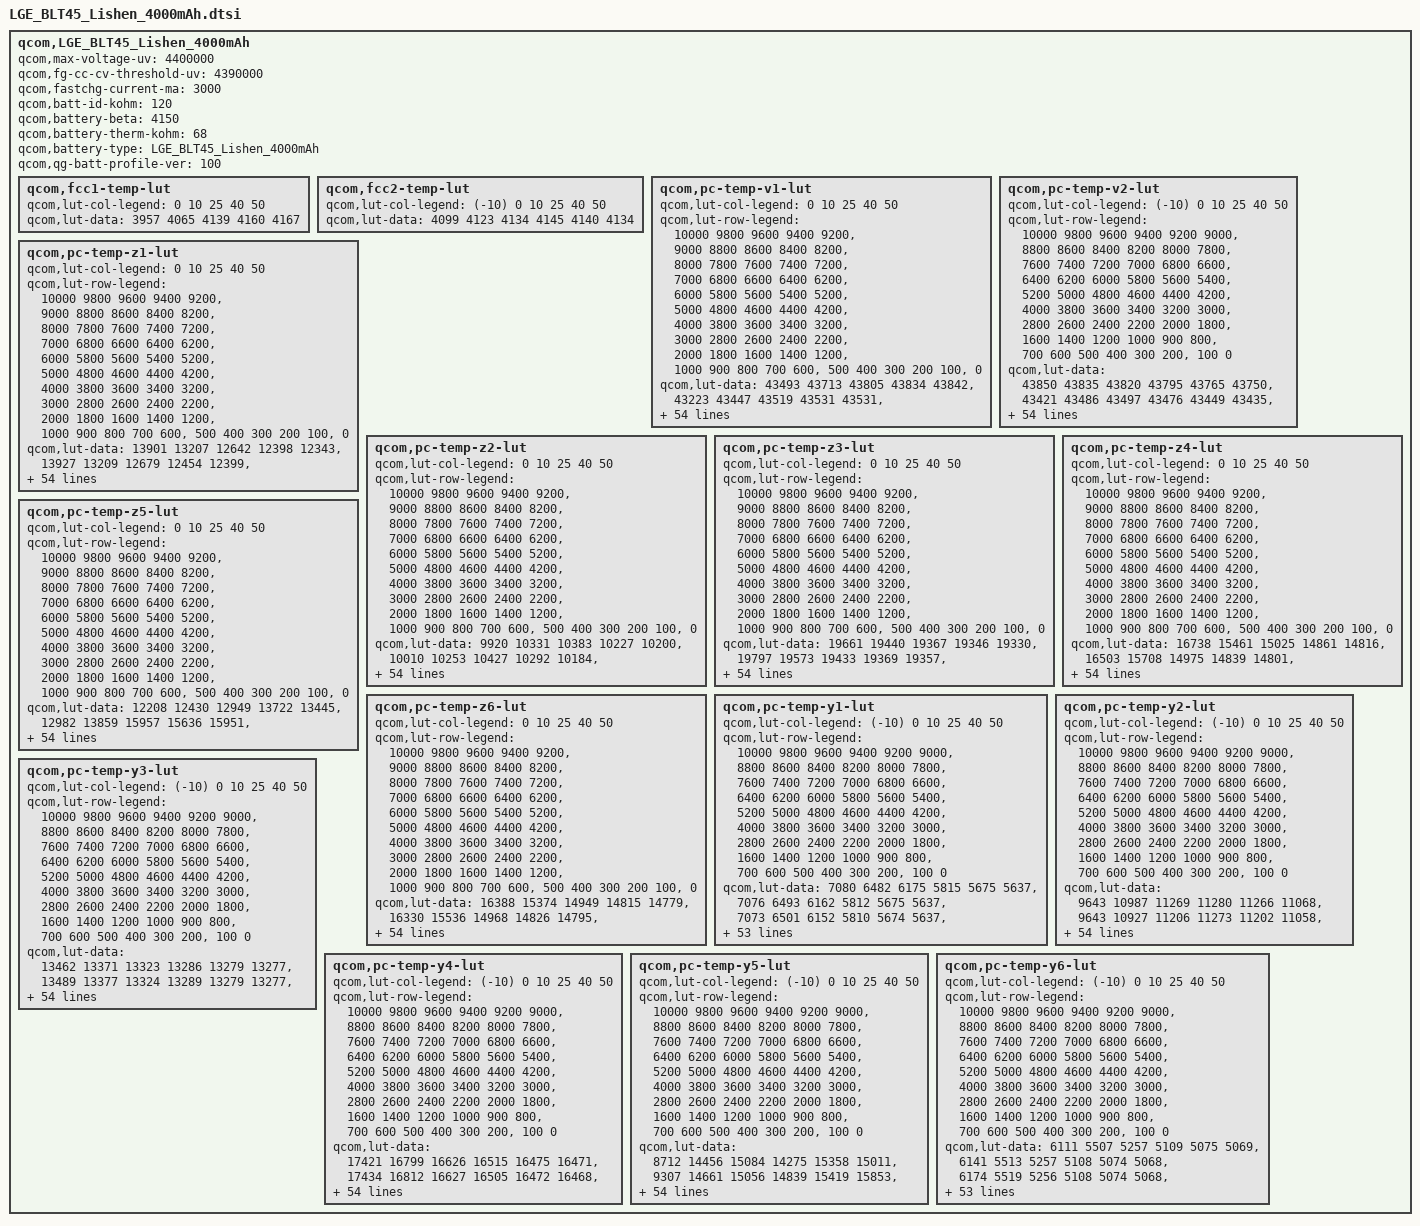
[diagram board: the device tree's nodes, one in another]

qcom,LGE_BLT45_Lishen_4000mAh {
    /* 3833608_LGE_BLT45_4000mAh_averaged_MasterSlave_Feb14th2019 */
    qcom,max-voltage-uv = <4400000>;
    qcom,fg-cc-cv-threshold-uv = <4390000>;
    qcom,fastchg-current-ma = <3000>;
    qcom,batt-id-kohm = <120>;
    qcom,battery-beta = <4150>;
    qcom,battery-therm-kohm = <68>;
    qcom,battery-type = "LGE_BLT45_Lishen_4000mAh";
    qcom,qg-batt-profile-ver = <100>;

	qcom,fcc1-temp-lut {
		qcom,lut-col-legend = <0 10 25 40 50>;
		qcom,lut-data = <3957 4065 4139 4160 4167>;
	};

	qcom,fcc2-temp-lut {
		qcom,lut-col-legend = <(-10) 0 10 25 40 50>;
		qcom,lut-data = <4099 4123 4134 4145 4140 4134>;
	};

	qcom,pc-temp-v1-lut {
		qcom,lut-col-legend = <0 10 25 40 50>;
		qcom,lut-row-legend = <10000 9800 9600 9400 9200>,
			<9000 8800 8600 8400 8200>,
			<8000 7800 7600 7400 7200>,
			<7000 6800 6600 6400 6200>,
			<6000 5800 5600 5400 5200>,
			<5000 4800 4600 4400 4200>,
			<4000 3800 3600 3400 3200>,
			<3000 2800 2600 2400 2200>,
			<2000 1800 1600 1400 1200>,
			<1000 900 800 700 600>,
			<500 400 300 200 100>,
			<0>;
		qcom,lut-data = <43493 43713 43805 43834 43842>,
			<43223 43447 43519 43531 43531>,
			<42963 43188 43263 43274 43282>,
			<42717 42944 43019 43032 43042>,
			<42480 42699 42779 42797 42804>,
			<42247 42457 42538 42560 42569>,
			<42018 42222 42301 42326 42337>,
			<41795 41990 42066 42094 42107>,
			<41575 41764 41834 41865 41879>,
			<41361 41543 41608 41639 41654>,
			<41154 41327 41386 41415 41431>,
			<40957 41118 41171 41195 41211>,
			<40763 40917 40962 40982 40997>,
			<40566 40722 40761 40776 40789>,
			<40370 40522 40564 40577 40589>,
			<40189 40324 40368 40388 40399>,
			<40023 40147 40182 40207 40218>,
			<39867 39987 40017 40036 40045>,
			<39722 39836 39864 39874 39880>,
			<39585 39695 39715 39719 39722>,
			<39450 39555 39579 39578 39579>,
			<39315 39388 39422 39426 39428>,
			<39182 39188 39179 39212 39220>,
			<39045 38995 38918 38965 38976>,
			<38906 38809 38772 38797 38803>,
			<38768 38648 38682 38683 38686>,
			<38619 38554 38598 38585 38585>,
			<38492 38493 38511 38491 38487>,
			<38415 38438 38430 38404 38397>,
			<38359 38383 38355 38325 38314>,
			<38317 38332 38288 38253 38238>,
			<38286 38283 38228 38187 38170>,
			<38260 38237 38177 38131 38111>,
			<38235 38195 38130 38078 38055>,
			<38212 38157 38092 38032 38003>,
			<38188 38122 38056 37989 37952>,
			<38166 38090 38018 37942 37896>,
			<38137 38060 37982 37894 37836>,
			<38089 38016 37934 37834 37766>,
			<38005 37932 37856 37755 37682>,
			<37905 37828 37753 37656 37583>,
			<37788 37717 37641 37547 37474>,
			<37651 37588 37510 37418 37349>,
			<37482 37425 37357 37267 37196>,
			<37343 37271 37207 37121 37050>,
			<37227 37157 37098 37023 36963>,
			<37182 37118 37063 36993 36933>,
			<37144 37087 37042 36970 36909>,
			<37112 37062 37022 36949 36889>,
			<37069 37029 36983 36904 36836>,
			<36902 36852 36789 36682 36592>,
			<36478 36437 36376 36262 36165>,
			<35904 35863 35811 35697 35598>,
			<35110 35070 35040 34927 34825>,
			<33720 33754 33847 33740 33635>,
			<30000 30000 30000 30000 30000>;
	};

	qcom,pc-temp-v2-lut {
		qcom,lut-col-legend = <(-10) 0 10 25 40 50>;
		qcom,lut-row-legend = <10000 9800 9600 9400 9200 9000>,
			<8800 8600 8400 8200 8000 7800>,
			<7600 7400 7200 7000 6800 6600>,
			<6400 6200 6000 5800 5600 5400>,
			<5200 5000 4800 4600 4400 4200>,
			<4000 3800 3600 3400 3200 3000>,
			<2800 2600 2400 2200 2000 1800>,
			<1600 1400 1200 1000 900 800>,
			<700 600 500 400 300 200>,
			<100 0>;
		qcom,lut-data = <43850 43835 43820 43795 43765 43750>,
			<43421 43486 43497 43476 43449 43435>,
			<43054 43169 43199 43181 43157 43145>,
			<42765 42888 42930 42916 42893 42883>,
			<42535 42639 42687 42676 42655 42646>,
			<42306 42397 42448 42440 42419 42412>,
			<42062 42154 42209 42202 42183 42176>,
			<41819 41916 41974 41967 41949 41943>,
			<41582 41684 41743 41737 41720 41714>,
			<41348 41456 41517 41510 41493 41488>,
			<41131 41237 41296 41287 41271 41267>,
			<40944 41028 41081 41069 41054 41050>,
			<40750 40824 40871 40856 40842 40839>,
			<40505 40624 40666 40651 40640 40635>,
			<40223 40424 40464 40451 40444 40438>,
			<39967 40211 40270 40258 40255 40249>,
			<39736 39981 40084 40070 40073 40069>,
			<39516 39756 39896 39893 39899 39897>,
			<39295 39544 39704 39735 39739 39736>,
			<39082 39342 39507 39576 39581 39577>,
			<38892 39153 39299 39385 39408 39406>,
			<38720 38973 39082 39168 39222 39225>,
			<38566 38810 38896 38970 39032 39039>,
			<38424 38662 38742 38790 38826 38833>,
			<38300 38527 38606 38633 38644 38649>,
			<38210 38404 38486 38510 38517 38520>,
			<38139 38291 38378 38406 38416 38418>,
			<38079 38188 38279 38311 38322 38323>,
			<38028 38089 38190 38224 38234 38233>,
			<37982 38006 38107 38145 38155 38151>,
			<37934 37946 38031 38073 38085 38078>,
			<37886 37898 37960 38005 38019 38009>,
			<37837 37853 37895 37943 37960 37950>,
			<37785 37814 37834 37884 37906 37898>,
			<37732 37772 37783 37825 37845 37835>,
			<37676 37726 37746 37768 37770 37744>,
			<37615 37676 37708 37706 37686 37641>,
			<37550 37618 37660 37635 37597 37541>,
			<37480 37551 37599 37556 37501 37442>,
			<37403 37476 37529 37478 37415 37354>,
			<37313 37391 37445 37404 37342 37280>,
			<37214 37291 37346 37313 37253 37193>,
			<37112 37171 37229 37199 37141 37080>,
			<37008 37038 37092 37078 37020 36960>,
			<36903 36904 36933 36931 36879 36822>,
			<36799 36778 36842 36878 36835 36782>,
			<36743 36727 36820 36863 36819 36766>,
			<36691 36678 36787 36840 36802 36751>,
			<36633 36619 36743 36804 36771 36719>,
			<36556 36536 36661 36718 36692 36631>,
			<36433 36364 36445 36449 36418 36326>,
			<36173 35970 35984 35939 35920 35827>,
			<35698 35382 35319 35268 35271 35175>,
			<34898 34494 34427 34311 34359 34273>,
			<33535 32960 33052 33027 33062 32905>,
			<31648 28310 27938 28209 28243 28177>;
	};

	qcom,pc-temp-z1-lut {
		qcom,lut-col-legend = <0 10 25 40 50>;
		qcom,lut-row-legend = <10000 9800 9600 9400 9200>,
			<9000 8800 8600 8400 8200>,
			<8000 7800 7600 7400 7200>,
			<7000 6800 6600 6400 6200>,
			<6000 5800 5600 5400 5200>,
			<5000 4800 4600 4400 4200>,
			<4000 3800 3600 3400 3200>,
			<3000 2800 2600 2400 2200>,
			<2000 1800 1600 1400 1200>,
			<1000 900 800 700 600>,
			<500 400 300 200 100>,
			<0>;
		qcom,lut-data = <13901 13207 12642 12398 12343>,
			<13927 13209 12679 12454 12399>,
			<13943 13216 12681 12455 12405>,
			<13935 13226 12681 12457 12408>,
			<13912 13228 12681 12461 12411>,
			<13907 13229 12678 12463 12414>,
			<13917 13226 12676 12465 12418>,
			<13924 13218 12675 12466 12421>,
			<13920 13211 12674 12467 12422>,
			<13908 13207 12674 12467 12423>,
			<13896 13204 12674 12467 12423>,
			<13876 13203 12673 12466 12423>,
			<13864 13202 12672 12466 12424>,
			<13869 13202 12672 12467 12425>,
			<13880 13201 12672 12468 12426>,
			<13882 13200 12671 12469 12428>,
			<13869 13200 12671 12470 12429>,
			<13856 13201 12672 12472 12431>,
			<13857 13203 12674 12474 12433>,
			<13863 13207 12677 12475 12434>,
			<13870 13214 12681 12477 12436>,
			<13881 13218 12685 12479 12437>,
			<13893 13221 12688 12482 12439>,
			<13904 13225 12693 12486 12443>,
			<13918 13229 12697 12490 12446>,
			<13926 13235 12701 12494 12450>,
			<13926 13242 12706 12499 12454>,
			<13926 13252 12711 12503 12457>,
			<13924 13260 12716 12506 12460>,
			<13921 13267 12720 12510 12463>,
			<13922 13272 12724 12513 12466>,
			<13927 13275 12728 12516 12469>,
			<13933 13277 12732 12519 12471>,
			<13939 13277 12735 12522 12474>,
			<13945 13278 12738 12525 12477>,
			<13954 13280 12742 12528 12479>,
			<13974 13283 12744 12531 12482>,
			<13997 13290 12747 12534 12485>,
			<14007 13297 12751 12537 12487>,
			<14019 13307 12756 12540 12490>,
			<14025 13316 12762 12544 12494>,
			<14017 13317 12766 12548 12496>,
			<14012 13319 12769 12551 12499>,
			<14001 13324 12773 12555 12503>,
			<13999 13333 12778 12559 12505>,
			<14017 13332 12783 12562 12507>,
			<13995 13339 12785 12562 12507>,
			<13994 13332 12789 12562 12508>,
			<14029 13331 12788 12564 12511>,
			<14018 13345 12792 12570 12515>,
			<14031 13355 12803 12576 12521>,
			<14025 13367 12813 12588 12531>,
			<14059 13388 12834 12603 12545>,
			<14072 13431 12866 12625 12566>,
			<14072 13431 12866 12625 12566>,
			<14072 13431 12866 12625 12566>;
	};

	qcom,pc-temp-z2-lut {
		qcom,lut-col-legend = <0 10 25 40 50>;
		qcom,lut-row-legend = <10000 9800 9600 9400 9200>,
			<9000 8800 8600 8400 8200>,
			<8000 7800 7600 7400 7200>,
			<7000 6800 6600 6400 6200>,
			<6000 5800 5600 5400 5200>,
			<5000 4800 4600 4400 4200>,
			<4000 3800 3600 3400 3200>,
			<3000 2800 2600 2400 2200>,
			<2000 1800 1600 1400 1200>,
			<1000 900 800 700 600>,
			<500 400 300 200 100>,
			<0>;
		qcom,lut-data = <9920 10331 10383 10227 10200>,
			<10010 10253 10427 10292 10184>,
			<10061 10253 10436 10443 10212>,
			<10074 10254 10423 10441 10280>,
			<10081 10243 10406 10426 10362>,
			<10081 10217 10391 10417 10371>,
			<10078 10197 10377 10400 10346>,
			<10072 10184 10376 10381 10311>,
			<10062 10177 10388 10353 10241>,
			<10048 10182 10400 10331 10181>,
			<10034 10202 10410 10318 10183>,
			<10018 10233 10418 10302 10196>,
			<10007 10336 10424 10306 10204>,
			<10003 10424 10431 10354 10209>,
			<10000 10394 10434 10385 10214>,
			<10001 10317 10437 10348 10232>,
			<10005 10306 10442 10295 10256>,
			<10013 10339 10456 10288 10262>,
			<10027 10375 10485 10298 10263>,
			<10053 10404 10506 10308 10266>,
			<10080 10431 10522 10322 10291>,
			<10108 10455 10534 10344 10325>,
			<10138 10480 10541 10405 10352>,
			<10172 10491 10546 10506 10377>,
			<10208 10488 10551 10561 10402>,
			<10237 10481 10558 10596 10432>,
			<10258 10472 10560 10610 10448>,
			<10276 10459 10560 10530 10350>,
			<10291 10453 10560 10413 10199>,
			<10304 10455 10551 10383 10176>,
			<10316 10458 10528 10371 10180>,
			<10326 10464 10521 10368 10187>,
			<10337 10479 10529 10371 10206>,
			<10350 10497 10542 10378 10236>,
			<10367 10520 10561 10395 10267>,
			<10385 10545 10588 10431 10305>,
			<10409 10568 10614 10471 10351>,
			<10435 10589 10642 10523 10416>,
			<10460 10607 10669 10568 10464>,
			<10485 10624 10697 10600 10486>,
			<10506 10638 10722 10625 10502>,
			<10521 10647 10737 10643 10506>,
			<10540 10654 10747 10658 10506>,
			<10572 10669 10758 10657 10515>,
			<13047 10769 10783 10645 10518>,
			<10722 10926 10818 10611 10479>,
			<14744 10958 10814 10639 10494>,
			<11724 10957 10811 10636 10503>,
			<13172 11231 10817 10645 10556>,
			<18833 12062 10848 10709 10654>,
			<15448 11325 10975 10596 10419>,
			<13945 11379 10927 10466 10264>,
			<10614 11218 10885 10396 10197>,
			<9902 10829 10829 10333 10111>,
			<9902 10829 10829 10333 10111>,
			<9902 10829 10829 10333 10111>;
	};

	qcom,pc-temp-z3-lut {
		qcom,lut-col-legend = <0 10 25 40 50>;
		qcom,lut-row-legend = <10000 9800 9600 9400 9200>,
			<9000 8800 8600 8400 8200>,
			<8000 7800 7600 7400 7200>,
			<7000 6800 6600 6400 6200>,
			<6000 5800 5600 5400 5200>,
			<5000 4800 4600 4400 4200>,
			<4000 3800 3600 3400 3200>,
			<3000 2800 2600 2400 2200>,
			<2000 1800 1600 1400 1200>,
			<1000 900 800 700 600>,
			<500 400 300 200 100>,
			<0>;
		qcom,lut-data = <19661 19440 19367 19346 19330>,
			<19797 19573 19433 19369 19357>,
			<19861 19624 19475 19407 19373>,
			<19859 19644 19481 19416 19389>,
			<19853 19647 19483 19420 19399>,
			<19846 19648 19484 19420 19400>,
			<19832 19648 19481 19419 19401>,
			<19819 19639 19478 19418 19400>,
			<19811 19626 19470 19409 19393>,
			<19805 19608 19463 19400 19384>,
			<19798 19586 19453 19395 19381>,
			<19789 19578 19443 19392 19379>,
			<19781 19584 19440 19391 19377>,
			<19770 19590 19438 19391 19376>,
			<19756 19583 19437 19391 19373>,
			<19745 19568 19437 19384 19369>,
			<19734 19554 19436 19375 19364>,
			<19722 19539 19434 19371 19361>,
			<19712 19527 19429 19370 19358>,
			<19702 19522 19424 19368 19356>,
			<19698 19519 19420 19365 19352>,
			<19696 19524 19418 19364 19350>,
			<19695 19551 19428 19365 19351>,
			<19700 19569 19442 19371 19357>,
			<19711 19570 19441 19379 19366>,
			<19719 19570 19425 19396 19386>,
			<19725 19569 19418 19406 19399>,
			<19729 19562 19430 19407 19397>,
			<19728 19557 19446 19407 19392>,
			<19721 19553 19452 19407 19389>,
			<19713 19550 19456 19403 19386>,
			<19704 19548 19456 19399 19382>,
			<19694 19547 19451 19394 19375>,
			<19685 19546 19445 19388 19367>,
			<19676 19544 19440 19382 19360>,
			<19667 19541 19434 19377 19353>,
			<19655 19536 19429 19372 19351>,
			<19644 19530 19423 19367 19350>,
			<19637 19525 19418 19364 19350>,
			<19632 19521 19414 19362 19351>,
			<19626 19516 19411 19361 19353>,
			<19611 19508 19409 19362 19352>,
			<19595 19498 19408 19365 19351>,
			<19584 19493 19404 19366 19356>,
			<19388 19470 19394 19365 19363>,
			<19260 19435 19384 19352 19347>,
			<19258 19429 19383 19345 19339>,
			<19258 19427 19372 19339 19336>,
			<19258 19371 19366 19338 19324>,
			<19256 19292 19360 19332 19319>,
			<19257 19362 19350 19351 19349>,
			<19257 19321 19353 19359 19356>,
			<19260 19315 19352 19358 19358>,
			<19265 19332 19351 19360 19363>,
			<19265 19332 19351 19360 19363>,
			<19265 19332 19351 19360 19363>;
	};

	qcom,pc-temp-z4-lut {
		qcom,lut-col-legend = <0 10 25 40 50>;
		qcom,lut-row-legend = <10000 9800 9600 9400 9200>,
			<9000 8800 8600 8400 8200>,
			<8000 7800 7600 7400 7200>,
			<7000 6800 6600 6400 6200>,
			<6000 5800 5600 5400 5200>,
			<5000 4800 4600 4400 4200>,
			<4000 3800 3600 3400 3200>,
			<3000 2800 2600 2400 2200>,
			<2000 1800 1600 1400 1200>,
			<1000 900 800 700 600>,
			<500 400 300 200 100>,
			<0>;
		qcom,lut-data = <16738 15461 15025 14861 14816>,
			<16503 15708 14975 14839 14801>,
			<16272 15550 15070 14893 14847>,
			<16032 15327 15002 14873 14838>,
			<15804 15198 14921 14836 14813>,
			<15633 15099 14878 14808 14792>,
			<15500 15026 14843 14785 14770>,
			<15392 14971 14816 14769 14756>,
			<15301 14929 14792 14760 14751>,
			<15225 14898 14777 14752 14746>,
			<15161 14874 14771 14745 14740>,
			<15106 14849 14767 14739 14733>,
			<15059 14813 14760 14731 14726>,
			<15020 14788 14750 14720 14720>,
			<14988 14789 14742 14713 14714>,
			<14961 14800 14735 14711 14708>,
			<14939 14800 14728 14709 14703>,
			<14919 14793 14721 14705 14697>,
			<14899 14786 14714 14698 14691>,
			<14882 14777 14710 14692 14686>,
			<14869 14769 14709 14688 14681>,
			<14859 14771 14708 14686 14679>,
			<14853 14797 14775 14733 14718>,
			<14854 14830 14878 14830 14810>,
			<14859 14879 14892 14849 14831>,
			<14869 14924 14877 14813 14788>,
			<14913 14924 14858 14777 14750>,
			<14954 14896 14825 14757 14737>,
			<14956 14869 14791 14741 14728>,
			<14950 14849 14771 14730 14720>,
			<14942 14831 14757 14721 14712>,
			<14927 14817 14749 14715 14705>,
			<14908 14805 14744 14710 14699>,
			<14892 14797 14741 14706 14695>,
			<14876 14791 14739 14703 14692>,
			<14861 14786 14737 14702 14690>,
			<14843 14779 14735 14702 14691>,
			<14827 14770 14733 14705 14695>,
			<14813 14766 14733 14709 14701>,
			<14801 14765 14737 14716 14707>,
			<14792 14764 14742 14723 14712>,
			<14787 14755 14738 14720 14710>,
			<14780 14737 14725 14709 14703>,
			<14759 14725 14721 14709 14703>,
			<14890 14712 14712 14707 14702>,
			<14979 14698 14686 14689 14682>,
			<14975 14694 14677 14686 14679>,
			<14969 14687 14673 14675 14666>,
			<14962 14742 14663 14652 14652>,
			<14954 14822 14663 14650 14646>,
			<14953 14748 14693 14663 14657>,
			<14973 14805 14697 14667 14664>,
			<14987 14819 14701 14669 14665>,
			<15014 14819 14705 14670 14661>,
			<15014 14819 14705 14670 14661>,
			<15014 14819 14705 14670 14661>;
	};

	qcom,pc-temp-z5-lut {
		qcom,lut-col-legend = <0 10 25 40 50>;
		qcom,lut-row-legend = <10000 9800 9600 9400 9200>,
			<9000 8800 8600 8400 8200>,
			<8000 7800 7600 7400 7200>,
			<7000 6800 6600 6400 6200>,
			<6000 5800 5600 5400 5200>,
			<5000 4800 4600 4400 4200>,
			<4000 3800 3600 3400 3200>,
			<3000 2800 2600 2400 2200>,
			<2000 1800 1600 1400 1200>,
			<1000 900 800 700 600>,
			<500 400 300 200 100>,
			<0>;
		qcom,lut-data = <12208 12430 12949 13722 13445>,
			<12982 13859 15957 15636 15951>,
			<13517 14821 16745 17906 16946>,
			<13799 15438 17339 18810 18410>,
			<14001 16073 17800 19291 19905>,
			<14209 16646 18207 19799 20755>,
			<14416 17072 18670 20273 21359>,
			<14633 17420 18905 20393 21533>,
			<14881 17641 19423 19948 20880>,
			<15143 17690 19747 19542 20191>,
			<15396 17714 19366 19642 20292>,
			<15672 17889 18855 19935 20715>,
			<15925 19426 18898 20390 21179>,
			<16210 20866 19333 21479 21816>,
			<16551 20842 19862 22111 22179>,
			<16775 20331 20548 21320 22005>,
			<17076 19981 21309 20245 21735>,
			<17489 19774 22032 20311 21865>,
			<18019 19679 22743 21065 22646>,
			<18745 20040 23250 21776 23315>,
			<19643 21069 23544 22456 23802>,
			<20894 24012 23974 22885 24105>,
			<22531 33048 26078 22390 22966>,
			<25116 38285 28753 21127 20227>,
			<28944 36250 27656 20172 19442>,
			<32105 32635 21434 19351 19506>,
			<34928 29860 18373 18977 19622>,
			<36738 27245 19388 19579 20025>,
			<36328 26218 21194 20752 20769>,
			<34597 26243 23359 21870 21737>,
			<32940 26307 26116 23100 23112>,
			<31473 26816 28068 24155 23652>,
			<30211 28490 29397 25011 23490>,
			<29441 30174 30381 25754 23324>,
			<28888 31992 31162 26514 23502>,
			<28445 33282 31737 27204 23986>,
			<27987 33385 31661 27260 24330>,
			<27663 33385 30588 26518 24752>,
			<28082 33358 29336 25506 24999>,
			<29737 33263 27912 24020 24361>,
			<30574 33067 26755 22611 23164>,
			<28247 31488 26740 22653 22305>,
			<26122 29263 26992 23271 21641>,
			<26368 29857 25763 23282 23126>,
			<17629 27899 24571 22813 24940>,
			<11660 23157 25083 21031 20998>,
			<11633 22106 25535 19328 18773>,
			<11628 21857 22895 19241 19314>,
			<11599 16024 21807 21890 19119>,
			<11574 12288 20874 21277 19111>,
			<11597 15411 17312 20756 22181>,
			<11558 13009 16632 20086 21034>,
			<11482 12637 15964 18771 19481>,
			<11519 12905 15414 17819 19163>,
			<11519 12905 15414 17819 19163>,
			<11519 12905 15414 17819 19163>;
	};

	qcom,pc-temp-z6-lut {
		qcom,lut-col-legend = <0 10 25 40 50>;
		qcom,lut-row-legend = <10000 9800 9600 9400 9200>,
			<9000 8800 8600 8400 8200>,
			<8000 7800 7600 7400 7200>,
			<7000 6800 6600 6400 6200>,
			<6000 5800 5600 5400 5200>,
			<5000 4800 4600 4400 4200>,
			<4000 3800 3600 3400 3200>,
			<3000 2800 2600 2400 2200>,
			<2000 1800 1600 1400 1200>,
			<1000 900 800 700 600>,
			<500 400 300 200 100>,
			<0>;
		qcom,lut-data = <16388 15374 14949 14815 14779>,
			<16330 15536 14968 14826 14795>,
			<16254 15481 15027 14870 14825>,
			<16146 15399 15000 14865 14826>,
			<16021 15342 14967 14853 14824>,
			<15926 15294 14947 14844 14821>,
			<15851 15253 14931 14835 14813>,
			<15788 15220 14916 14826 14805>,
			<15736 15191 14902 14817 14798>,
			<15692 15164 14890 14809 14791>,
			<15654 15139 14882 14803 14787>,
			<15619 15123 14875 14799 14783>,
			<15589 15111 14869 14794 14779>,
			<15561 15102 14864 14790 14775>,
			<15536 15096 14860 14786 14771>,
			<15517 15091 14856 14781 14767>,
			<15503 15085 14853 14776 14762>,
			<15491 15074 14848 14772 14757>,
			<15480 15065 14843 14768 14753>,
			<15470 15059 14840 14765 14750>,
			<15466 15055 14838 14762 14746>,
			<15464 15059 14837 14760 14744>,
			<15464 15084 14872 14783 14762>,
			<15467 15112 14925 14829 14807>,
			<15477 15138 14930 14840 14819>,
			<15490 15159 14918 14834 14813>,
			<15516 15158 14907 14828 14806>,
			<15537 15146 14901 14821 14800>,
			<15537 15133 14895 14815 14795>,
			<15534 15124 14891 14809 14789>,
			<15530 15117 14887 14804 14785>,
			<15521 15111 14884 14799 14780>,
			<15511 15107 14880 14794 14773>,
			<15502 15103 14876 14790 14767>,
			<15494 15101 14872 14785 14762>,
			<15487 15099 14869 14782 14758>,
			<15478 15095 14866 14780 14757>,
			<15471 15091 14862 14779 14758>,
			<15468 15090 14861 14778 14760>,
			<15467 15090 14862 14781 14763>,
			<15466 15090 14863 14784 14767>,
			<15461 15086 14862 14783 14766>,
			<15456 15077 14857 14781 14763>,
			<15450 15075 14854 14782 14766>,
			<15419 15063 14847 14781 14769>,
			<15400 15045 14832 14767 14753>,
			<15400 15043 14829 14762 14747>,
			<15400 15041 14822 14754 14740>,
			<15401 15038 14815 14744 14728>,
			<15404 15038 14814 14740 14723>,
			<15418 15050 14824 14757 14745>,
			<15442 15065 14832 14766 14754>,
			<15469 15081 14839 14770 14759>,
			<15518 15114 14848 14776 14765>,
			<15518 15114 14848 14776 14765>,
			<15518 15114 14848 14776 14765>;
	};

	qcom,pc-temp-y1-lut {
		qcom,lut-col-legend = <(-10) 0 10 25 40 50>;
		qcom,lut-row-legend = <10000 9800 9600 9400 9200 9000>,
			<8800 8600 8400 8200 8000 7800>,
			<7600 7400 7200 7000 6800 6600>,
			<6400 6200 6000 5800 5600 5400>,
			<5200 5000 4800 4600 4400 4200>,
			<4000 3800 3600 3400 3200 3000>,
			<2800 2600 2400 2200 2000 1800>,
			<1600 1400 1200 1000 900 800>,
			<700 600 500 400 300 200>,
			<100 0>;
		qcom,lut-data = <7080 6482 6175 5815 5675 5637>,
			<7076 6493 6162 5812 5675 5637>,
			<7073 6501 6152 5810 5674 5637>,
			<7070 6507 6144 5808 5673 5638>,
			<7068 6510 6139 5806 5672 5638>,
			<7067 6511 6137 5804 5672 5638>,
			<7063 6508 6139 5803 5672 5638>,
			<7057 6504 6142 5801 5672 5639>,
			<7054 6509 6141 5800 5671 5639>,
			<7052 6522 6138 5800 5670 5639>,
			<7051 6526 6136 5799 5669 5639>,
			<7051 6514 6133 5800 5669 5639>,
			<7052 6505 6130 5800 5669 5639>,
			<7052 6509 6130 5798 5670 5639>,
			<7054 6516 6129 5797 5671 5639>,
			<7058 6519 6130 5797 5671 5640>,
			<7077 6518 6136 5799 5671 5641>,
			<7091 6518 6139 5800 5671 5643>,
			<7080 6516 6135 5800 5672 5644>,
			<7061 6515 6129 5800 5673 5644>,
			<7056 6516 6131 5801 5674 5645>,
			<7055 6521 6137 5803 5675 5644>,
			<7055 6525 6140 5805 5676 5644>,
			<7060 6527 6138 5807 5677 5646>,
			<7067 6529 6136 5808 5679 5648>,
			<7068 6527 6137 5810 5681 5650>,
			<7071 6523 6141 5813 5682 5651>,
			<7073 6521 6142 5816 5684 5653>,
			<7073 6522 6143 5819 5687 5655>,
			<7071 6524 6144 5823 5689 5656>,
			<7071 6528 6149 5826 5692 5658>,
			<7071 6535 6156 5829 5694 5660>,
			<7072 6535 6158 5831 5697 5662>,
			<7077 6529 6157 5833 5699 5665>,
			<7084 6526 6157 5836 5702 5667>,
			<7092 6531 6159 5838 5704 5670>,
			<7100 6538 6160 5841 5706 5672>,
			<7097 6539 6160 5843 5708 5674>,
			<7071 6536 6159 5845 5710 5676>,
			<7054 6535 6159 5847 5712 5677>,
			<7065 6538 6161 5851 5713 5678>,
			<7077 6539 6164 5853 5714 5679>,
			<7067 6536 6167 5853 5715 5682>,
			<7066 6537 6182 5856 5719 5682>,
			<7073 6551 6171 5859 5721 5684>,
			<7086 6565 6184 5863 5725 5687>,
			<7107 6559 6190 5865 5725 5688>,
			<7095 6552 6181 5869 5726 5690>,
			<7096 6554 6187 5871 5728 5689>,
			<7112 6564 6187 5872 5729 5691>,
			<7102 6566 6195 5880 5731 5695>,
			<7117 6597 6205 5888 5740 5702>,
			<7188 6618 6224 5906 5751 5712>,
			<7374 6727 6259 5930 5766 5726>,
			<7374 6727 6259 5930 5766 5726>,
			<7374 6727 6259 5930 5766 5726>;
	};

	qcom,pc-temp-y2-lut {
		qcom,lut-col-legend = <(-10) 0 10 25 40 50>;
		qcom,lut-row-legend = <10000 9800 9600 9400 9200 9000>,
			<8800 8600 8400 8200 8000 7800>,
			<7600 7400 7200 7000 6800 6600>,
			<6400 6200 6000 5800 5600 5400>,
			<5200 5000 4800 4600 4400 4200>,
			<4000 3800 3600 3400 3200 3000>,
			<2800 2600 2400 2200 2000 1800>,
			<1600 1400 1200 1000 900 800>,
			<700 600 500 400 300 200>,
			<100 0>;
		qcom,lut-data = <9643 10987 11269 11280 11266 11068>,
			<9643 10927 11206 11273 11202 11058>,
			<9643 10869 11145 11257 11131 11030>,
			<9954 10815 11088 11235 11064 10995>,
			<10315 10769 11037 11207 11014 10963>,
			<10451 10733 10993 11176 10993 10943>,
			<10459 10700 10955 11132 10995 10924>,
			<10465 10679 10922 11093 11000 10906>,
			<10489 10678 10895 11077 10986 10893>,
			<10542 10682 10873 11067 10954 10877>,
			<10603 10687 10859 11054 10940 10872>,
			<10686 10706 10848 11033 10940 10874>,
			<10745 10737 10842 11019 10940 10874>,
			<10732 10792 10850 11019 10917 10870>,
			<10696 10864 10872 11025 10882 10860>,
			<10690 10899 10907 11030 10874 10852>,
			<10727 10914 10977 11033 10877 10841>,
			<10756 10929 11030 11040 10885 10836>,
			<10430 10952 11049 11088 10934 10853>,
			<9851 10979 11065 11146 11001 10878>,
			<9708 11008 11094 11168 11046 10888>,
			<9690 11040 11139 11179 11085 10909>,
			<9683 11073 11189 11200 11109 10937>,
			<9681 11106 11251 11263 11122 11022>,
			<9680 11139 11304 11320 11132 11103>,
			<9679 11176 11332 11340 11143 11120>,
			<9676 11212 11351 11352 11157 11130>,
			<9674 11205 11365 11364 11184 11149>,
			<9670 11028 11376 11377 11257 11201>,
			<9667 10826 11384 11386 11314 11248>,
			<9664 10726 11391 11407 11333 11272>,
			<9662 10642 11398 11434 11347 11290>,
			<9660 10484 11422 11440 11366 11294>,
			<9659 10186 11485 11441 11390 11295>,
			<9657 9961 11514 11440 11399 11297>,
			<9656 9862 11454 11417 11381 11302>,
			<9656 9795 11371 11396 11362 11308>,
			<9655 9751 11332 11409 11366 11310>,
			<9654 9720 11305 11440 11378 11309>,
			<9654 9700 11270 11464 11375 11299>,
			<9654 9689 11214 11485 11322 11231>,
			<9654 9679 11144 11483 11300 11207>,
			<9654 9671 11058 11455 11323 11236>,
			<9654 9666 10994 11448 11310 11215>,
			<9654 9664 10580 11469 11343 11261>,
			<9654 9659 10500 11424 11265 11078>,
			<9653 9658 10735 11382 11266 11023>,
			<9653 9657 10632 11351 11183 10959>,
			<9653 9656 10537 11328 11146 10892>,
			<9653 9655 10375 11289 11129 10892>,
			<9653 9654 9829 11230 11082 10885>,
			<9652 9653 9696 11141 11015 10839>,
			<9649 9652 9667 11006 10909 10733>,
			<9648 9649 9656 10836 10731 10586>,
			<9648 9649 9656 10836 10731 10586>,
			<9648 9649 9656 10836 10731 10586>;
	};

	qcom,pc-temp-y3-lut {
		qcom,lut-col-legend = <(-10) 0 10 25 40 50>;
		qcom,lut-row-legend = <10000 9800 9600 9400 9200 9000>,
			<8800 8600 8400 8200 8000 7800>,
			<7600 7400 7200 7000 6800 6600>,
			<6400 6200 6000 5800 5600 5400>,
			<5200 5000 4800 4600 4400 4200>,
			<4000 3800 3600 3400 3200 3000>,
			<2800 2600 2400 2200 2000 1800>,
			<1600 1400 1200 1000 900 800>,
			<700 600 500 400 300 200>,
			<100 0>;
		qcom,lut-data = <13462 13371 13323 13286 13279 13277>,
			<13489 13377 13324 13289 13279 13277>,
			<13518 13383 13326 13291 13280 13278>,
			<13544 13389 13327 13293 13280 13278>,
			<13561 13394 13328 13294 13280 13279>,
			<13567 13399 13329 13294 13281 13279>,
			<13561 13403 13330 13294 13281 13279>,
			<13553 13407 13331 13293 13281 13279>,
			<13551 13408 13332 13293 13281 13280>,
			<13551 13409 13333 13294 13281 13280>,
			<13548 13410 13335 13294 13281 13280>,
			<13529 13410 13340 13295 13281 13280>,
			<13506 13409 13343 13295 13282 13280>,
			<13493 13408 13344 13296 13283 13280>,
			<13484 13404 13345 13297 13286 13280>,
			<13473 13399 13345 13298 13287 13281>,
			<13460 13391 13346 13301 13288 13283>,
			<13448 13381 13346 13303 13288 13285>,
			<13439 13373 13343 13306 13291 13286>,
			<13430 13366 13338 13309 13294 13286>,
			<13418 13360 13332 13307 13294 13287>,
			<13399 13355 13324 13303 13293 13287>,
			<13382 13350 13319 13299 13292 13287>,
			<13365 13347 13316 13295 13285 13282>,
			<13353 13343 13314 13292 13280 13277>,
			<13354 13339 13313 13291 13279 13277>,
			<13364 13336 13313 13290 13279 13277>,
			<13378 13326 13312 13290 13278 13278>,
			<13401 13288 13313 13290 13278 13277>,
			<13434 13260 13313 13290 13278 13276>,
			<13474 13259 13312 13290 13279 13276>,
			<13525 13259 13311 13290 13280 13275>,
			<13586 13260 13309 13290 13280 13276>,
			<13661 13261 13304 13289 13280 13277>,
			<13750 13264 13302 13289 13280 13278>,
			<13852 13267 13306 13289 13280 13277>,
			<13971 13272 13312 13289 13281 13276>,
			<14104 13284 13313 13287 13280 13276>,
			<14254 13308 13313 13284 13279 13275>,
			<14415 13325 13313 13283 13278 13275>,
			<14586 13340 13313 13284 13278 13276>,
			<14763 13363 13315 13284 13278 13277>,
			<14947 13418 13322 13284 13278 13278>,
			<15109 13476 13322 13288 13279 13278>,
			<15090 13517 13303 13284 13277 13276>,
			<15315 13659 13315 13284 13279 13279>,
			<15429 13760 13336 13291 13282 13280>,
			<15555 13907 13344 13293 13285 13285>,
			<15694 14082 13358 13298 13289 13287>,
			<15879 14326 13376 13302 13291 13288>,
			<16181 14679 13400 13300 13286 13284>,
			<16929 15256 13462 13301 13285 13284>,
			<20820 16322 13632 13309 13289 13288>,
			<49440 22952 14408 13320 13295 13295>,
			<49440 22952 14408 13320 13295 13295>,
			<49440 22952 14408 13320 13295 13295>;
	};

	qcom,pc-temp-y4-lut {
		qcom,lut-col-legend = <(-10) 0 10 25 40 50>;
		qcom,lut-row-legend = <10000 9800 9600 9400 9200 9000>,
			<8800 8600 8400 8200 8000 7800>,
			<7600 7400 7200 7000 6800 6600>,
			<6400 6200 6000 5800 5600 5400>,
			<5200 5000 4800 4600 4400 4200>,
			<4000 3800 3600 3400 3200 3000>,
			<2800 2600 2400 2200 2000 1800>,
			<1600 1400 1200 1000 900 800>,
			<700 600 500 400 300 200>,
			<100 0>;
		qcom,lut-data = <17421 16799 16626 16515 16475 16471>,
			<17434 16812 16627 16505 16472 16468>,
			<17450 16837 16627 16500 16470 16466>,
			<17468 16865 16628 16497 16469 16464>,
			<17487 16887 16629 16496 16468 16463>,
			<17508 16896 16630 16496 16468 16462>,
			<17537 16896 16631 16500 16469 16463>,
			<17561 16897 16632 16506 16471 16464>,
			<17566 16902 16635 16510 16474 16466>,
			<17568 16915 16642 16514 16478 16467>,
			<17578 16933 16650 16519 16483 16469>,
			<17671 16961 16659 16525 16487 16473>,
			<17758 16996 16671 16533 16491 16477>,
			<17692 17046 16695 16542 16494 16482>,
			<17507 17099 16731 16553 16498 16487>,
			<17368 17102 16769 16565 16504 16491>,
			<17265 17043 16814 16578 16512 16495>,
			<17187 16975 16835 16596 16523 16501>,
			<17138 16917 16825 16638 16539 16512>,
			<17100 16860 16802 16676 16559 16527>,
			<17057 16809 16755 16667 16576 16543>,
			<17008 16762 16665 16627 16593 16560>,
			<16960 16724 16608 16584 16594 16564>,
			<16908 16693 16580 16530 16532 16517>,
			<16864 16668 16563 16495 16475 16472>,
			<16851 16648 16553 16490 16472 16468>,
			<16845 16631 16547 16488 16471 16466>,
			<16843 16632 16544 16489 16472 16466>,
			<16846 16679 16542 16493 16475 16469>,
			<16850 16718 16541 16498 16481 16474>,
			<16856 16719 16540 16504 16487 16480>,
			<16864 16719 16538 16512 16496 16488>,
			<16871 16720 16535 16518 16506 16499>,
			<16878 16729 16531 16524 16519 16512>,
			<16885 16740 16529 16526 16524 16517>,
			<16893 16755 16532 16520 16514 16504>,
			<16901 16770 16537 16510 16500 16485>,
			<16916 16777 16542 16497 16487 16477>,
			<16947 16782 16549 16483 16473 16472>,
			<16968 16788 16557 16481 16471 16472>,
			<16966 16809 16568 16485 16480 16480>,
			<16966 16815 16579 16488 16481 16482>,
			<16982 16795 16590 16489 16477 16476>,
			<16997 16797 16596 16493 16483 16483>,
			<16960 16784 16606 16473 16453 16449>,
			<16981 16811 16632 16488 16465 16462>,
			<17010 16860 16639 16497 16476 16481>,
			<17044 16909 16684 16519 16500 16512>,
			<17089 16992 16751 16554 16536 16549>,
			<17149 17106 16841 16582 16552 16560>,
			<17183 17232 16913 16558 16495 16482>,
			<17221 17312 16935 16542 16479 16474>,
			<17818 17404 17073 16586 16489 16483>,
			<29127 20383 17373 16686 16533 16525>,
			<29127 20383 17373 16686 16533 16525>,
			<29127 20383 17373 16686 16533 16525>;
	};

	qcom,pc-temp-y5-lut {
		qcom,lut-col-legend = <(-10) 0 10 25 40 50>;
		qcom,lut-row-legend = <10000 9800 9600 9400 9200 9000>,
			<8800 8600 8400 8200 8000 7800>,
			<7600 7400 7200 7000 6800 6600>,
			<6400 6200 6000 5800 5600 5400>,
			<5200 5000 4800 4600 4400 4200>,
			<4000 3800 3600 3400 3200 3000>,
			<2800 2600 2400 2200 2000 1800>,
			<1600 1400 1200 1000 900 800>,
			<700 600 500 400 300 200>,
			<100 0>;
		qcom,lut-data = <8712 14456 15084 14275 15358 15011>,
			<9307 14661 15056 14839 15419 15853>,
			<10616 14783 14976 15158 15418 16362>,
			<12113 14844 14857 15293 15369 16621>,
			<13323 14865 14713 15304 15284 16714>,
			<13780 14866 14555 15237 15175 16717>,
			<13821 14795 14363 14726 14980 16374>,
			<13841 14664 14152 14133 14732 15932>,
			<13846 14489 13919 13927 14432 15691>,
			<13847 14237 13677 13801 14057 15417>,
			<13867 14025 13621 13705 13826 15255>,
			<14171 13827 13732 13508 13591 14774>,
			<14645 13715 13821 13331 13447 14339>,
			<15232 13938 13686 13186 13736 14072>,
			<15903 14502 13442 13033 14238 13735>,
			<16065 15068 13487 13046 14297 13778>,
			<15925 15742 14092 13270 14113 14334>,
			<15667 16131 14831 13560 14013 14657>,
			<14859 16166 15787 13875 14137 14419>,
			<13583 16155 16599 14312 14411 14113>,
			<12833 16214 16660 15212 15163 14450>,
			<12373 16383 16599 16683 16691 15663>,
			<11989 16459 16558 17421 17215 16189>,
			<11603 16396 16616 17543 16713 16182>,
			<11290 16271 16714 17517 16162 16174>,
			<11124 16089 16850 17453 15977 16360>,
			<11011 15757 17091 17358 15858 16717>,
			<10964 15062 17355 17367 15717 16731>,
			<11011 12717 17781 17402 15449 16047>,
			<11078 10969 18072 17444 15303 15339>,
			<11091 10945 18137 17454 15589 14902>,
			<11117 10944 18143 17455 16023 14581>,
			<11160 10966 17715 17488 16152 14677>,
			<11244 11101 16148 17521 16183 15310>,
			<11338 11229 15426 17632 16324 15846>,
			<11420 11291 16900 18316 17577 16195>,
			<11493 11349 18550 18928 18809 16449>,
			<11520 11486 18502 18128 18699 16545>,
			<11497 11729 17925 16331 18184 16604>,
			<11479 11851 17250 15832 17622 16600>,
			<11496 11806 16294 15898 16646 16386>,
			<11485 11807 16160 15835 16268 16353>,
			<11409 11957 16925 15606 16329 16584>,
			<11352 11766 16184 17579 16257 16626>,
			<11261 11670 13076 16156 17420 18183>,
			<11410 11597 13941 15300 15771 16374>,
			<11335 11480 15774 17144 15860 15653>,
			<11454 11714 15481 16265 16114 16279>,
			<11572 11798 15350 16497 15713 15143>,
			<11672 12092 14738 16260 15608 14840>,
			<11958 12181 13203 16478 15606 15488>,
			<11679 11520 12258 17031 15562 15770>,
			<10297 11067 11407 17162 16861 16328>,
			<9090 9495 10979 16920 18321 18987>,
			<9090 9495 10979 16920 18321 18987>,
			<9090 9495 10979 16920 18321 18987>;
	};

	qcom,pc-temp-y6-lut {
		qcom,lut-col-legend = <(-10) 0 10 25 40 50>;
		qcom,lut-row-legend = <10000 9800 9600 9400 9200 9000>,
			<8800 8600 8400 8200 8000 7800>,
			<7600 7400 7200 7000 6800 6600>,
			<6400 6200 6000 5800 5600 5400>,
			<5200 5000 4800 4600 4400 4200>,
			<4000 3800 3600 3400 3200 3000>,
			<2800 2600 2400 2200 2000 1800>,
			<1600 1400 1200 1000 900 800>,
			<700 600 500 400 300 200>,
			<100 0>;
		qcom,lut-data = <6111 5507 5257 5109 5075 5069>,
			<6141 5513 5257 5108 5074 5068>,
			<6174 5519 5256 5108 5074 5068>,
			<6204 5525 5255 5108 5074 5068>,
			<6226 5528 5254 5108 5074 5068>,
			<6233 5530 5252 5109 5075 5069>,
			<6228 5528 5251 5109 5075 5069>,
			<6220 5526 5250 5110 5076 5070>,
			<6212 5526 5250 5111 5077 5070>,
			<6202 5526 5251 5113 5078 5071>,
			<6199 5527 5253 5115 5079 5072>,
			<6206 5531 5257 5117 5080 5073>,
			<6212 5538 5262 5119 5082 5074>,
			<6191 5548 5269 5122 5084 5076>,
			<6134 5559 5278 5126 5087 5077>,
			<6089 5558 5288 5131 5090 5079>,
			<6057 5534 5300 5136 5093 5082>,
			<6028 5507 5306 5143 5096 5085>,
			<5999 5485 5301 5157 5103 5089>,
			<5972 5464 5290 5169 5111 5094>,
			<5952 5447 5272 5166 5115 5099>,
			<5935 5431 5241 5150 5119 5104>,
			<5925 5419 5221 5135 5118 5104>,
			<5922 5410 5212 5117 5096 5087>,
			<5919 5403 5206 5105 5076 5070>,
			<5924 5399 5204 5103 5074 5069>,
			<5947 5397 5203 5103 5074 5069>,
			<5975 5394 5203 5103 5074 5069>,
			<6009 5390 5204 5104 5075 5070>,
			<6051 5388 5205 5106 5077 5071>,
			<6101 5391 5206 5109 5079 5072>,
			<6160 5400 5206 5111 5083 5074>,
			<6224 5412 5206 5113 5086 5078>,
			<6294 5428 5204 5115 5090 5083>,
			<6371 5448 5204 5116 5091 5085>,
			<6455 5472 5209 5114 5089 5080>,
			<6549 5502 5218 5112 5086 5075>,
			<6652 5537 5225 5108 5082 5072>,
			<6766 5579 5231 5103 5077 5071>,
			<6888 5626 5239 5102 5076 5071>,
			<7013 5680 5249 5104 5079 5074>,
			<7145 5740 5262 5106 5079 5075>,
			<7287 5809 5280 5107 5078 5074>,
			<7411 5889 5294 5112 5080 5076>,
			<7391 5931 5289 5104 5071 5065>,
			<7562 6077 5331 5110 5076 5072>,
			<7652 6179 5365 5119 5082 5079>,
			<7757 6309 5403 5126 5091 5091>,
			<7874 6468 5462 5141 5104 5103>,
			<8027 6685 5537 5153 5110 5107>,
			<8263 6988 5614 5147 5091 5083>,
			<8834 7442 5715 5146 5086 5081>,
			<11783 8260 5978 5170 5094 5088>,
			<30547 13841 6720 5214 5114 5108>,
			<30547 13841 6720 5214 5114 5108>,
			<30547 13841 6720 5214 5114 5108>;
	};

};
